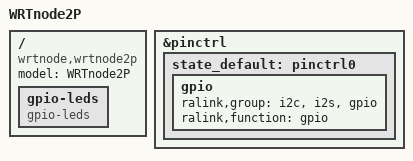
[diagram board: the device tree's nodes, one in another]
/dts-v1/;

#include "WRTNODE2.dtsi"

/ {
	compatible = "wrtnode,wrtnode2p", "wrtnode,wrtnode2", "mediatek,mt7628an-soc";
	model = "WRTnode2P";

	gpio-leds {
		compatible = "gpio-leds";

		// led_indicator: indicator {
		// 	label = "wrtnode:blue:indicator";
		// 	gpios = <&gpio0 1 GPIO_ACTIVE_HIGH>;
		// 	default-on;
		// };
	};

	// gpio-keys-polled {
	// 	compatible = "gpio-keys-polled";
	// 	poll-interval = <20>;

	// 	reset {
	// 		label = "reset";
	// 		gpios = <&gpio0 5 GPIO_ACTIVE_LOW>;
	// 		linux,code = <KEY_RESTART>;
	// 	};
	// };
};

&pinctrl {
	state_default: pinctrl0 {
		gpio {
			ralink,group = "i2c", "i2s", "gpio";
			ralink,function = "gpio";
		};
	};
};
